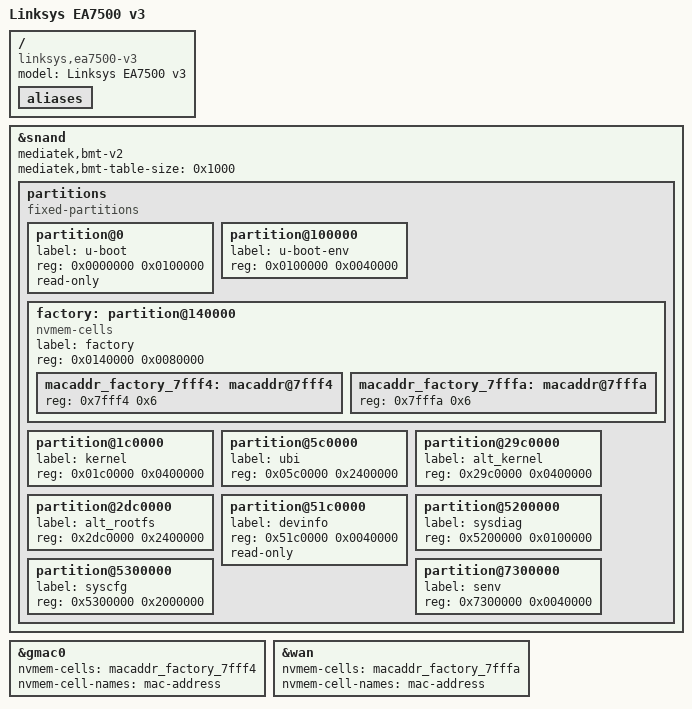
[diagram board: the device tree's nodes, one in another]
// SPDX-License-Identifier: (GPL-2.0-only OR MIT)

/dts-v1/;
#include "mt7629-linksys-ea7xxx.dtsi"

/ {
	model = "Linksys EA7500 v3";
	compatible = "linksys,ea7500-v3", "mediatek,mt7629";

	aliases {
		//label-mac-device = &wan;
	};
};

&snand {
	mediatek,bmt-v2;
	mediatek,bmt-table-size = <0x1000>;

	partitions {
		compatible = "fixed-partitions";
		#address-cells = <1>;
		#size-cells = <1>;

		partition@0 {
			label = "u-boot"; // Bootloader
			reg = <0x0000000 0x0100000>;
			read-only;
		};

		partition@100000 {
			label = "u-boot-env";
			reg = <0x0100000 0x0040000>;
		};

		factory: partition@140000 {
			label = "factory";
			reg = <0x0140000 0x0080000>;
		};

		partition@1c0000 {
			label = "kernel";
			reg = <0x01c0000 0x0400000>;
		};

		partition@5c0000 {
			label = "ubi";
			reg = <0x05c0000 0x2400000>;
		};

		partition@29c0000 {
			label = "alt_kernel";
			reg = <0x29c0000 0x0400000>;
		};

		partition@2dc0000 {
			label = "alt_rootfs";
			reg = <0x2dc0000 0x2400000>;
		};

		/*
		partition@1c0000 {
			label = "firmware1";
			compatible = "denx,fit";
			openwrt,cmdline-match = "mtdparts=master";
			reg = <0x01c0000 0x2800000>;
		};

		partition@29c0000 {
			label = "firmware2";
			compatible = "denx,fit";
			openwrt,cmdline-match = "mtdparts=slave";
			reg = <0x29c0000 0x2800000>;
		};
		*/

		partition@51c0000 {
			label = "devinfo";
			reg = <0x51c0000 0x0040000>;
			read-only;
		};

		partition@5200000 {
			label = "sysdiag";
			reg = <0x5200000 0x0100000>;
		};

		partition@5300000 {
			label = "syscfg";
			reg = <0x5300000 0x2000000>;
		};

		partition@7300000 {
			label = "senv";
			reg = <0x7300000 0x0040000>;
		};
	};
};

/*
&wmac {
	mediatek,mtd-eeprom = <&factory 0x0000>;
	status = "okay";
};

&wmac1 {
	mediatek,mtd-eeprom = <&factory 0x05000>;
};
*/

&gmac0 {
	nvmem-cells = <&macaddr_factory_7fff4>;
	nvmem-cell-names = "mac-address";
};

&wan {
	nvmem-cells = <&macaddr_factory_7fffa>;
	nvmem-cell-names = "mac-address";
};

&factory {
	compatible = "nvmem-cells";
	#address-cells = <1>;
	#size-cells = <1>;

	macaddr_factory_7fff4: macaddr@7fff4 {
		reg = <0x7fff4 0x6>;
	};

	macaddr_factory_7fffa: macaddr@7fffa {
		reg = <0x7fffa 0x6>;
	};
};
